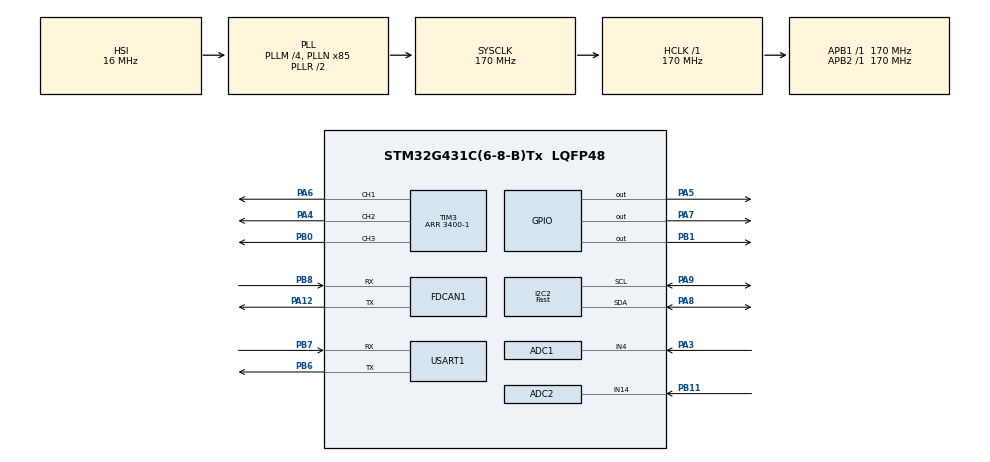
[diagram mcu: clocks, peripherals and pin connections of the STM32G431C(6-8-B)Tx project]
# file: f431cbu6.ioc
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ADC1.Channel-0\#ChannelRegularConversion=ADC_CHANNEL_4
ADC1.EnableInjectedConversion=ENABLE
ADC1.ExternalTrigConv=ADC_SOFTWARE_START
ADC1.ExternalTrigInjecConv=ADC_EXTERNALTRIGINJEC_T3_TRGO
ADC1.InjNumberOfConversion=1
ADC1.InjectedChannel-1\#ChannelInjectedConversion=ADC_CHANNEL_4
ADC1.InjectedOffsetNumber-1\#ChannelInjectedConversion=ADC_OFFSET_NONE
ADC1.InjectedRank-1\#ChannelInjectedConversion=1
ADC1.InjectedSamplingTime-1\#ChannelInjectedConversion=ADC_SAMPLETIME_12CYCLES_5
ADC1.NbrOfConversionFlag=1
ADC1.OffsetNumber-0\#ChannelRegularConversion=ADC_OFFSET_NONE
ADC1.Rank-0\#ChannelRegularConversion=1
ADC1.SamplingTime-0\#ChannelRegularConversion=ADC_SAMPLETIME_12CYCLES_5
ADC1.master=1
ADC2.Channel-1\#ChannelRegularConversion=ADC_CHANNEL_14
ADC2.EnableInjectedConversion=ENABLE
ADC2.EnableRegularConversion=ENABLE
ADC2.ExternalTrigInjecConv=ADC_EXTERNALTRIGINJEC_T3_TRGO
ADC2.InjNumberOfConversion=1
ADC2.InjectedChannel-2\#ChannelInjectedConversion=ADC_CHANNEL_14
ADC2.InjectedOffsetNumber-2\#ChannelInjectedConversion=ADC_OFFSET_NONE
ADC2.InjectedRank-2\#ChannelInjectedConversion=1
ADC2.InjectedSamplingTime-2\#ChannelInjectedConversion=ADC_SAMPLETIME_12CYCLES_5
ADC2.NbrOfConversionFlag=1
ADC2.OffsetNumber-1\#ChannelRegularConversion=ADC_OFFSET_NONE
ADC2.Rank-1\#ChannelRegularConversion=1
ADC2.SamplingTime-1\#ChannelRegularConversion=ADC_SAMPLETIME_12CYCLES_5
Dma.ADC1.1.Direction=DMA_PERIPH_TO_MEMORY
Dma.ADC1.1.EventEnable=DISABLE
Dma.ADC1.1.Instance=DMA1_Channel2
Dma.ADC1.1.MemDataAlignment=DMA_MDATAALIGN_HALFWORD
Dma.ADC1.1.MemInc=DMA_MINC_ENABLE
Dma.ADC1.1.Mode=DMA_CIRCULAR
Dma.ADC1.1.PeriphDataAlignment=DMA_PDATAALIGN_HALFWORD
Dma.ADC1.1.PeriphInc=DMA_PINC_DISABLE
Dma.ADC1.1.Polarity=HAL_DMAMUX_REQ_GEN_RISING
Dma.ADC1.1.Priority=DMA_PRIORITY_LOW
Dma.ADC1.1.RequestNumber=1
Dma.ADC1.1.SignalID=NONE
Dma.ADC1.1.SyncEnable=DISABLE
Dma.ADC1.1.SyncPolarity=HAL_DMAMUX_SYNC_NO_EVENT
Dma.ADC1.1.SyncRequestNumber=1
Dma.ADC1.1.SyncSignalID=NONE
Dma.ADC2.2.Direction=DMA_PERIPH_TO_MEMORY
Dma.ADC2.2.EventEnable=DISABLE
Dma.ADC2.2.Instance=DMA1_Channel3
Dma.ADC2.2.MemDataAlignment=DMA_MDATAALIGN_HALFWORD
Dma.ADC2.2.MemInc=DMA_MINC_ENABLE
Dma.ADC2.2.Mode=DMA_CIRCULAR
Dma.ADC2.2.PeriphDataAlignment=DMA_PDATAALIGN_HALFWORD
Dma.ADC2.2.PeriphInc=DMA_PINC_DISABLE
Dma.ADC2.2.Polarity=HAL_DMAMUX_REQ_GEN_RISING
Dma.ADC2.2.Priority=DMA_PRIORITY_LOW
Dma.ADC2.2.RequestNumber=1
Dma.ADC2.2.SignalID=NONE
Dma.ADC2.2.SyncEnable=DISABLE
Dma.ADC2.2.SyncPolarity=HAL_DMAMUX_SYNC_NO_EVENT
Dma.ADC2.2.SyncRequestNumber=1
Dma.ADC2.2.SyncSignalID=NONE
Dma.I2C2_RX.0.Direction=DMA_PERIPH_TO_MEMORY
Dma.I2C2_RX.0.EventEnable=DISABLE
Dma.I2C2_RX.0.Instance=DMA1_Channel1
Dma.I2C2_RX.0.MemDataAlignment=DMA_MDATAALIGN_BYTE
Dma.I2C2_RX.0.MemInc=DMA_MINC_ENABLE
Dma.I2C2_RX.0.Mode=DMA_NORMAL
Dma.I2C2_RX.0.PeriphDataAlignment=DMA_PDATAALIGN_BYTE
Dma.I2C2_RX.0.PeriphInc=DMA_PINC_DISABLE
Dma.I2C2_RX.0.Polarity=HAL_DMAMUX_REQ_GEN_RISING
Dma.I2C2_RX.0.Priority=DMA_PRIORITY_LOW
Dma.I2C2_RX.0.RequestNumber=1
Dma.I2C2_RX.0.SignalID=NONE
Dma.I2C2_RX.0.SyncEnable=DISABLE
Dma.I2C2_RX.0.SyncPolarity=HAL_DMAMUX_SYNC_NO_EVENT
Dma.I2C2_RX.0.SyncRequestNumber=1
Dma.I2C2_RX.0.SyncSignalID=NONE
Dma.Request0=I2C2_RX
Dma.Request1=ADC1
Dma.Request2=ADC2
FDCAN1.CalculateBaudRateNominal=3541666
FDCAN1.CalculateTimeBitNominal=282
FDCAN1.CalculateTimeQuantumNominal=94.11764705882354
I2C2.I2C_Speed_Mode=I2C_Fast
I2C2.Timing=0x40621236
Mcu.Family=STM32G4
Mcu.Name=STM32G431C(6-8-B)Tx
Mcu.Package=LQFP48
NVIC.DMA1_Channel1_IRQn=true\:0\:0\:false\:false\:true\:false\:true\:true
NVIC.DMA1_Channel2_IRQn=true\:0\:0\:false\:false\:true\:false\:true\:true
NVIC.DMA1_Channel3_IRQn=true\:0\:0\:false\:false\:true\:false\:true\:true
NVIC.PriorityGroup=NVIC_PRIORITYGROUP_4
NVIC.TIM6_DAC_IRQn=true\:0\:0\:false\:false\:true\:true\:true\:true
PA12.Mode=FDCAN_Activate
PA12.Signal=FDCAN1_TX
PA13.Mode=Serial_Wire
PA13.Signal=SYS_JTMS-SWDIO
PA14.Mode=Serial_Wire
PA14.Signal=SYS_JTCK-SWCLK
PA3.Mode=IN4-Single-Ended
PA3.Signal=ADC1_IN4
PA4.Signal=S_TIM3_CH2
PA5.PinState=GPIO_PIN_SET
PA5.Signal=GPIO_Output
PA6.Signal=S_TIM3_CH1
PA7.PinState=GPIO_PIN_SET
PA7.Signal=GPIO_Output
PA8.Mode=I2C
PA8.Signal=I2C2_SDA
PA9.Mode=I2C
PA9.Signal=I2C2_SCL
PB0.Signal=S_TIM3_CH3
PB1.PinState=GPIO_PIN_SET
PB1.Signal=GPIO_Output
PB11.Signal=SharedAnalog_PB11
PB6.Mode=Asynchronous
PB6.Signal=USART1_TX
PB7.Mode=Asynchronous
PB7.Signal=USART1_RX
PB8-BOOT0.Mode=FDCAN_Activate
PB8-BOOT0.Signal=FDCAN1_RX
PF0-OSC_IN.Mode=HSE-External-Oscillator
PF0-OSC_IN.Signal=RCC_OSC_IN
PF1-OSC_OUT.Mode=HSE-External-Oscillator
PF1-OSC_OUT.Signal=RCC_OSC_OUT
ProjectManager.HeapSize=0x200
ProjectManager.StackSize=0x400
ProjectManager.TargetToolchain=MDK-ARM V5.32
RCC.ADC12Freq_Value=170000000
RCC.AHBFreq_Value=170000000
RCC.APB1Freq_Value=170000000
RCC.APB1TimFreq_Value=170000000
RCC.APB2Freq_Value=170000000
RCC.APB2TimFreq_Value=170000000
RCC.CortexFreq_Value=170000000
RCC.EXTERNAL_CLOCK_VALUE=12288000
RCC.HCLKFreq_Value=170000000
RCC.HSE_VALUE=8000000
RCC.HSI48_VALUE=48000000
RCC.HSI_VALUE=16000000
RCC.LSE_VALUE=32768
RCC.PLLM=RCC_PLLM_DIV4
RCC.PLLN=85
RCC.SYSCLKFreq_VALUE=170000000
RCC.SYSCLKSource=RCC_SYSCLKSOURCE_PLLCLK
RCC.USBFreq_Value=170000000
RCC.VCOOutputFreq_Value=340000000
SH.S_TIM3_CH1.0=TIM3_CH1,PWM Generation1 CH1
SH.S_TIM3_CH2.0=TIM3_CH2,PWM Generation2 CH2
SH.S_TIM3_CH3.0=TIM3_CH3,PWM Generation3 CH3
SH.SharedAnalog_PB11.0=ADC1_IN14
SH.SharedAnalog_PB11.1=ADC2_IN14,IN14-Single-Ended
TIM3.AutoReloadPreload=TIM_AUTORELOAD_PRELOAD_ENABLE
TIM3.Channel-Output\ Compare4\ No\ Output=TIM_CHANNEL_4
TIM3.Channel-PWM\ Generation1\ CH1=TIM_CHANNEL_1
TIM3.Channel-PWM\ Generation2\ CH2=TIM_CHANNEL_2
TIM3.Channel-PWM\ Generation3\ CH3=TIM_CHANNEL_3
TIM3.CounterMode=TIM_COUNTERMODE_CENTERALIGNED1
TIM3.OC4Preload=DISABLE
TIM3.PeriodNoDither=3400-1
TIM3.TIM_MasterOutputTrigger=TIM_TRGO_OC4REF
TIM6.AutoReloadPreload=TIM_AUTORELOAD_PRELOAD_ENABLE
USART1.VirtualMode-Asynchronous=VM_ASYNC
VP_RTC_VS_RTC_Activate.Mode=RTC_Enabled
VP_SYS_VS_DBSignals.Mode=DisableDeadBatterySignals
VP_TIM3_VS_ClockSourceINT.Mode=Internal
VP_TIM3_VS_no_output4.Mode=Output Compare4 No Output
VP_TIM6_VS_ClockSourceINT.Mode=Enable_Timer
board=custom

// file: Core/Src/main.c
/* USER CODE BEGIN Header */
/**
  ******************************************************************************
  * @file           : main.c
  * @brief          : STM32G431 FOC 主程序
  ******************************************************************************
  */
/* USER CODE END Header */
#include "main.h"
#include "adc.h"
#include "dma.h"
#include "fdcan.h"
#include "i2c.h"
#include "rtc.h"
#include "tim.h"
#include "usart.h"
#include "gpio.h"

/* USER CODE BEGIN Includes */
#include "foc_main_g431.h"
/* USER CODE END Includes */

void SystemClock_Config(void);

int main(void)
{

  /* MCU Configuration--------------------------------------------------------*/

  /* Reset of all peripherals, Initializes the Flash interface and the Systick. */
  HAL_Init();

  /* Configure the system clock */
  SystemClock_Config();

  /* Initialize all configured peripherals */
  MX_GPIO_Init();
  MX_DMA_Init();
  MX_ADC1_Init();
  MX_ADC2_Init();
  MX_FDCAN1_Init();
  MX_I2C2_Init();
  MX_USART1_UART_Init();
  MX_TIM3_Init();
  MX_TIM6_Init();
  MX_RTC_Init();
  /* USER CODE BEGIN 2 */
  foc_main_init();
  /* USER CODE END 2 */

  /* Infinite loop */
  while (1)
  {

    /* USER CODE BEGIN 3 */
    foc_main_loop();
  }
  /* USER CODE END 3 */
}

void SystemClock_Config(void)
{
  RCC_OscInitTypeDef RCC_OscInitStruct = {0};
  RCC_ClkInitTypeDef RCC_ClkInitStruct = {0};

  /** Configure the main internal regulator output voltage
  */
  HAL_PWREx_ControlVoltageScaling(PWR_REGULATOR_VOLTAGE_SCALE1_BOOST);

  /** Initializes the RCC Oscillators according to the specified parameters
  * in the RCC_OscInitTypeDef structure.
  */
  RCC_OscInitStruct.OscillatorType = RCC_OSCILLATORTYPE_HSI|RCC_OSCILLATORTYPE_LSI;
  RCC_OscInitStruct.HSIState = RCC_HSI_ON;
  RCC_OscInitStruct.HSICalibrationValue = RCC_HSICALIBRATION_DEFAULT;
  RCC_OscInitStruct.LSIState = RCC_LSI_ON;
  RCC_OscInitStruct.PLL.PLLState = RCC_PLL_ON;
  RCC_OscInitStruct.PLL.PLLSource = RCC_PLLSOURCE_HSI;
  RCC_OscInitStruct.PLL.PLLM = RCC_PLLM_DIV4;
  RCC_OscInitStruct.PLL.PLLN = 85;
  RCC_OscInitStruct.PLL.PLLP = RCC_PLLP_DIV2;
  RCC_OscInitStruct.PLL.PLLQ = RCC_PLLQ_DIV2;
  RCC_OscInitStruct.PLL.PLLR = RCC_PLLR_DIV2;
  if (HAL_RCC_OscConfig(&RCC_OscInitStruct) != HAL_OK)
  {
    Error_Handler();
  }

  /** Initializes the CPU, AHB and APB buses clocks
  */
  RCC_ClkInitStruct.ClockType = RCC_CLOCKTYPE_HCLK|RCC_CLOCKTYPE_SYSCLK
                              |RCC_CLOCKTYPE_PCLK1|RCC_CLOCKTYPE_PCLK2;
  RCC_ClkInitStruct.SYSCLKSource = RCC_SYSCLKSOURCE_PLLCLK;
  RCC_ClkInitStruct.AHBCLKDivider = RCC_SYSCLK_DIV1;
  RCC_ClkInitStruct.APB1CLKDivider = RCC_HCLK_DIV1;
  RCC_ClkInitStruct.APB2CLKDivider = RCC_HCLK_DIV1;

  if (HAL_RCC_ClockConfig(&RCC_ClkInitStruct, FLASH_LATENCY_4) != HAL_OK)
  {
    Error_Handler();
  }
}

void Error_Handler(void)
{
  __disable_irq();
  while (1)
  {
  }
}
